# MB9BF56xx register map
File version: 1.0
CPU: 
Registers are 8-bit, read-write, reset 0x0 unless marked. A register's access mark holds for its fields unless they carry their own. Offsets are from the block's base; [hi:lo] are bit positions; {n}, {i} and the like mark numbered series.

## MFS0 — peripheral MFS0
Base 0x40038000
Same registers: MFS{n} {0x40038000+0x100*n} (n=1..15)
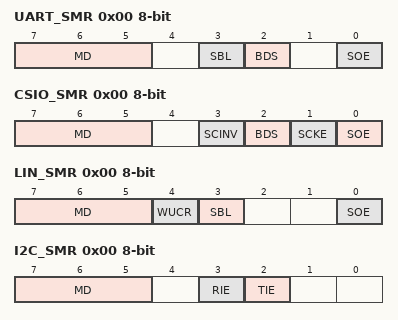
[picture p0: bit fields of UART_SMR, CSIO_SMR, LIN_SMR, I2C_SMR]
0x00 UART_SMR (UART view)
  [7:5] MD, [3] SBL, [2] BDS, [0] SOE
0x00 CSIO_SMR (CSIO view)
  [7:5] MD, [3] SCINV, [2] BDS, [1] SCKE, [0] SOE
0x00 LIN_SMR (LIN view)
  [7:5] MD, [4] WUCR, [3] SBL, [0] SOE
0x00 I2C_SMR (I2C view)
  [7:5] MD, [3] RIE, [2] TIE
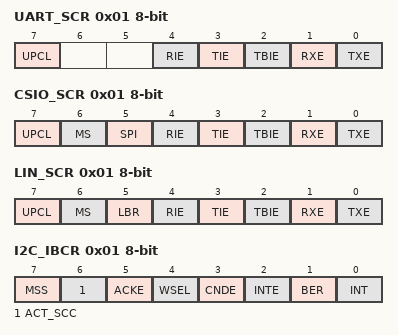
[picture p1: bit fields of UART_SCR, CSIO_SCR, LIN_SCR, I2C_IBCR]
0x01 UART_SCR (UART view)
  [7] UPCL, [4] RIE, [3] TIE, [2] TBIE, [1] RXE, [0] TXE
0x01 CSIO_SCR (CSIO view)
  [7] UPCL, [6] MS, [5] SPI, [4] RIE, [3] TIE, [2] TBIE, [1] RXE, [0] TXE
0x01 LIN_SCR (LIN view)
  [7] UPCL, [6] MS, [5] LBR, [4] RIE, [3] TIE, [2] TBIE, [1] RXE, [0] TXE
0x01 I2C_IBCR (I2C view)
  [7] MSS, [6] ACT_SCC, [5] ACKE, [4] WSEL, [3] CNDE, [2] INTE, [1] BER ro, [0] INT
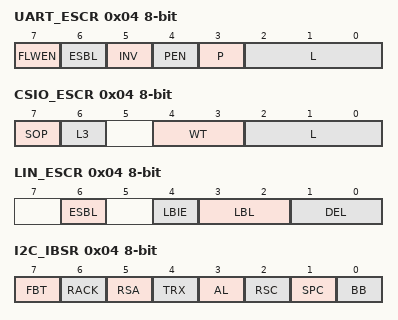
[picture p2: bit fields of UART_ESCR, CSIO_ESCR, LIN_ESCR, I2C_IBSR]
0x04 UART_ESCR (UART view)
  [7] FLWEN, [6] ESBL, [5] INV, [4] PEN, [3] P, [2:0] L
0x04 CSIO_ESCR (reset mask 0xCF) (CSIO view)
  [7] SOP, [6] L3, [4:3] WT, [2:0] L
0x04 LIN_ESCR (LIN view)
  [6] ESBL, [4] LBIE, [3:2] LBL, [1:0] DEL
0x04 I2C_IBSR (I2C view)
  [7] FBT ro, [6] RACK ro, [5] RSA ro, [4] TRX ro, [3] AL ro, [2] RSC, [1] SPC, [0] BB ro
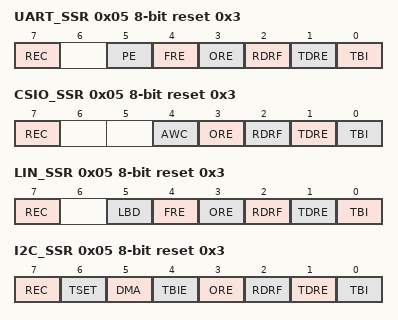
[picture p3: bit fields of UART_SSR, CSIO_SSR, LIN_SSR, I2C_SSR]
0x05 UART_SSR reset 0x3 (UART view)
  [7] REC, [5] PE ro, [4] FRE ro, [3] ORE ro, [2] RDRF ro, [1] TDRE ro, [0] TBI ro
0x05 CSIO_SSR reset 0x3 (CSIO view)
  [7] REC, [4] AWC, [3] ORE ro, [2] RDRF ro, [1] TDRE ro, [0] TBI ro
0x05 LIN_SSR reset 0x3 (LIN view)
  [7] REC, [5] LBD, [4] FRE ro, [3] ORE ro, [2] RDRF ro, [1] TDRE ro, [0] TBI ro
0x05 I2C_SSR reset 0x3 (I2C view)
  [7] REC, [6] TSET, [5] DMA, [4] TBIE, [3] ORE ro, [2] RDRF ro, [1] TDRE ro, [0] TBI ro
0x08 UART_RDR 16-bit ro (UART view)
  [8:0] D
0x08 UART_TDR 16-bit wo reset 0x1FF (UART view)
  [8:0] D
0x08 CSIO_RDR 16-bit ro (CSIO view)
  [15:0] D
0x08 CSIO_TDR 16-bit wo reset 0xFFFF (CSIO view)
  [15:0] D
0x08 LIN_RDR 16-bit ro (LIN view)
  [7:0] D
0x08 LIN_TDR 16-bit wo reset 0xFF (LIN view)
  [7:0] D
0x08 I2C_RDR 16-bit ro (I2C view)
  [7:0] D
0x08 I2C_TDR 16-bit wo reset 0xFF (I2C view)
  [7:0] D
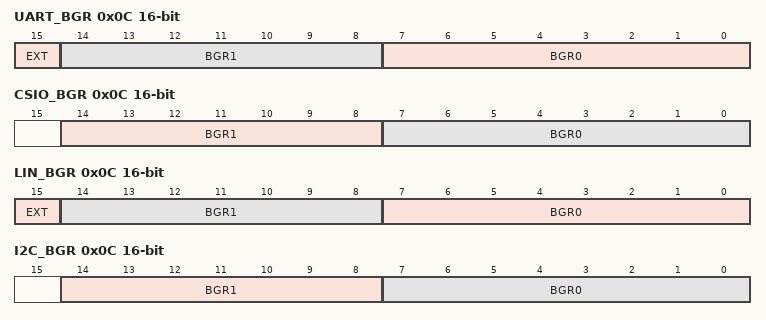
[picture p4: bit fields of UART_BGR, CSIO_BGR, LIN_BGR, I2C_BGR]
0x0C UART_BGR 16-bit (UART view)
  [15] EXT, [14:8] BGR1, [7:0] BGR0
0x0C CSIO_BGR 16-bit (CSIO view)
  [14:8] BGR1, [7:0] BGR0
0x0C LIN_BGR 16-bit (LIN view)
  [15] EXT, [14:8] BGR1, [7:0] BGR0
0x0C I2C_BGR 16-bit (I2C view)
  [14:8] BGR1, [7:0] BGR0
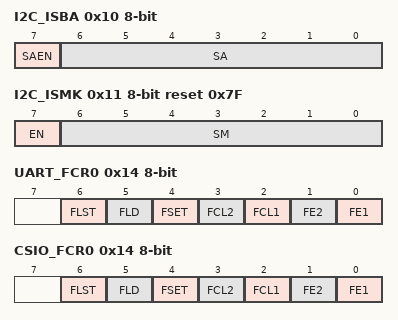
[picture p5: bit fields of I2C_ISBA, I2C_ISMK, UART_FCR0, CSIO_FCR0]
0x10 I2C_ISBA (I2C view)
  [7] SAEN, [6:0] SA
0x11 I2C_ISMK reset 0x7F (I2C view)
  [7] EN, [6:0] SM
0x14 UART_FCR0 (UART view)
  [6] FLST ro, [5] FLD, [4] FSET, [3] FCL2, [2] FCL1, [1] FE2, [0] FE1
0x14 CSIO_FCR0 (CSIO view)
  [6] FLST ro, [5] FLD, [4] FSET, [3] FCL2, [2] FCL1, [1] FE2, [0] FE1
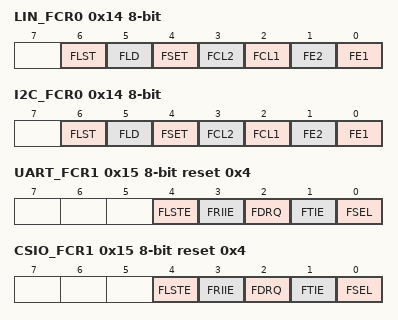
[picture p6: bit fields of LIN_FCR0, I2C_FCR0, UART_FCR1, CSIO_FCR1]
0x14 LIN_FCR0 (LIN view)
  [6] FLST ro, [5] FLD, [4] FSET, [3] FCL2, [2] FCL1, [1] FE2, [0] FE1
0x14 I2C_FCR0 (I2C view)
  [6] FLST ro, [5] FLD, [4] FSET, [3] FCL2, [2] FCL1, [1] FE2, [0] FE1
0x15 UART_FCR1 reset 0x4 (UART view)
  [4] FLSTE, [3] FRIIE, [2] FDRQ, [1] FTIE, [0] FSEL
0x15 CSIO_FCR1 reset 0x4 (CSIO view)
  [4] FLSTE, [3] FRIIE, [2] FDRQ, [1] FTIE, [0] FSEL
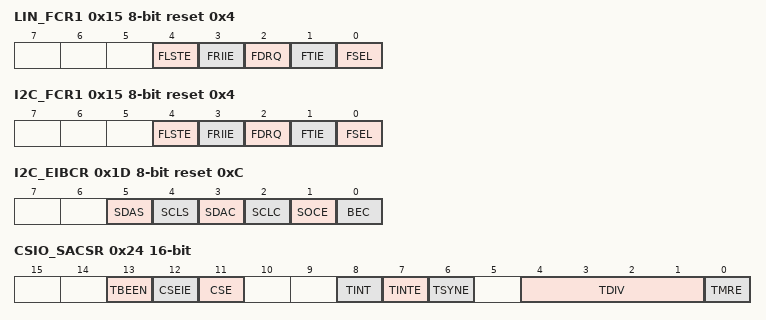
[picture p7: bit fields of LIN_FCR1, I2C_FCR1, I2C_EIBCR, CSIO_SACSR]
0x15 LIN_FCR1 reset 0x4 (LIN view)
  [4] FLSTE, [3] FRIIE, [2] FDRQ, [1] FTIE, [0] FSEL
0x15 I2C_FCR1 reset 0x4 (I2C view)
  [4] FLSTE, [3] FRIIE, [2] FDRQ, [1] FTIE, [0] FSEL
0x18 UART_FBYTE1 (UART view)
0x18 CSIO_FBYTE1 (CSIO view)
0x18 LIN_FBYTE1 (LIN view)
0x18 I2C_FBYTE1 (I2C view)
0x19 UART_FBYTE2 (UART view)
0x19 CSIO_FBYTE2 (CSIO view)
0x19 LIN_FBYTE2 (LIN view)
0x19 I2C_FBYTE2 (I2C view)
0x1C CSIO_SCSTR0 (CSIO view)
  [7:0] CSHD
0x1C I2C_NFCR (I2C view)
  [4:0] NFT
0x1D CSIO_SCSTR1 (CSIO view)
  [7:0] CSSU
0x1D I2C_EIBCR reset 0xC (I2C view)
  [5] SDAS, [4] SCLS, [3] SDAC, [2] SCLC, [1] SOCE, [0] BEC
0x20 CSIO_SCSTR2 16-bit (CSIO view)
  [15:0] CSDS
0x21 CSIO_SCSTR3 (CSIO view)
0x24 CSIO_SACSR 16-bit (CSIO view)
  [13] TBEEN, [12] CSEIE, [11] CSE, [8] TINT, [7] TINTE, [6] TSYNE, [4:1] TDIV, [0] TMRE
0x28 CSIO_STMR 16-bit ro (CSIO view)
  [15:0] TM
0x2C CSIO_STMCR 16-bit (CSIO view)
  [15:0] TC
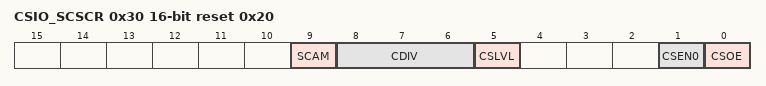
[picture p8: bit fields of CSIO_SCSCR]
0x30 CSIO_SCSCR 16-bit reset 0x20 (CSIO view)
  [9] SCAM, [8:6] CDIV, [5] CSLVL, [1] CSEN0, [0] CSOE
0x3C CSIO_TBYTE0 (CSIO view)
0x3D CSIO_TBYTE1 (CSIO view)
0x40 CSIO_TBYTE2 (CSIO view)
0x41 CSIO_TBYTE3 (CSIO view)
